# AT91SAM9X35 register map
Vendor: Atmel; Series: SAM9X; File version: 20130207
Registers are 32-bit, read-write, reset 0x0 unless marked. A register's access mark holds for its fields unless they carry their own. Offsets are from the block's base; [hi:lo] are bit positions; {n}, {i} and the like mark numbered series; 'fields as' and 'values as' point back to an identical list.

## PWM — Pulse Width Modulation Controller
Base 0xF8034000; register names take the prefix PWM_
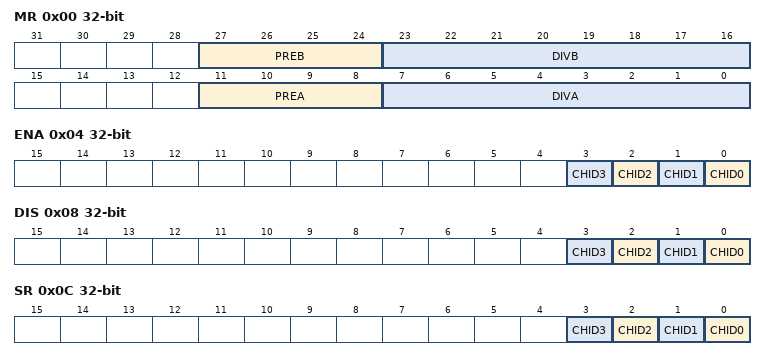
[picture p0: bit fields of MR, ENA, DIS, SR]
0x00 MR — PWM Mode Register
  [27:24] PREB
    0=MCK (Master Clock); 1=MCKDIV2 (Master Clock divided by 2); 2=MCKDIV4 (Master Clock divided by 4); 3=MCKDIV8 (Master Clock divided by 8); 4=MCKDIV16 (Master Clock divided by 16); 5=MCKDIV32 (Master Clock divided by 32); 6=MCKDIV64 (Master Clock divided by 64); 7=MCKDIV128 (Master Clock divided by 128); 8=MCKDIV256 (Master Clock divided by 256); 9=MCKDIV512 (Master Clock divided by 512); 10=MCKDIV1024 (Master Clock divided by 1024)
  [23:16] DIVB — CLKA, CLKB Divide Factor
    0=CLK_OFF (CLKA, CLKB clock is turned off); 1=CLK_DIV1 (CLKA, CLKB clock is clock selected by PREA, PREB)
  [11:8] PREA
    values as PREB
  [7:0] DIVA — CLKA, CLKB Divide Factor
    values as DIVB
0x04 ENA wo reset not defined — PWM Enable Register
  [n] CHID{n} (n=0..3) — Channel ID
0x08 DIS wo reset not defined — PWM Disable Register
  [n] CHID{n} (n=0..3) — Channel ID
0x0C SR ro — PWM Status Register
  [n] CHID{n} (n=0..3) — Channel ID
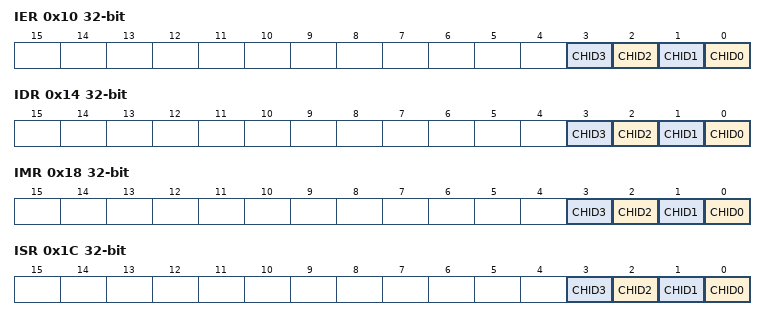
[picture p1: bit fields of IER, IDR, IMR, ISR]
0x10 IER wo reset not defined — PWM Interrupt Enable Register
  [n] CHID{n} (n=0..3) — Channel ID.
0x14 IDR wo reset not defined — PWM Interrupt Disable Register
  [n] CHID{n} (n=0..3) — Channel ID.
0x18 IMR ro — PWM Interrupt Mask Register
  [n] CHID{n} (n=0..3) — Channel ID.
0x1C ISR ro — PWM Interrupt Status Register
  [n] CHID{n} (n=0..3) — Channel ID
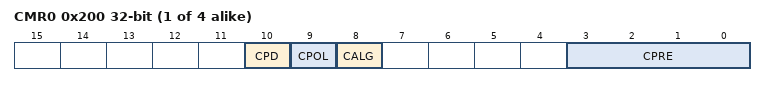
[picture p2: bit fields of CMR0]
{0x200+0x20*i} CMR{i} (i=0..3) — PWM Channel Mode Register (ch_num = {i})
  [10] CPD — Channel Update Period
  [9] CPOL — Channel Polarity
  [8] CALG — Channel Alignment
  [3:0] CPRE — Channel Pre-scaler
    0=MCK (Master Clock); 1=MCKDIV2 (Master Clock divided by 2); 2=MCKDIV4 (Master Clock divided by 4); 3=MCKDIV8 (Master Clock divided by 8); 4=MCKDIV16 (Master Clock divided by 16); 5=MCKDIV32 (Master Clock divided by 32); 6=MCKDIV64 (Master Clock divided by 64); 7=MCKDIV128 (Master Clock divided by 128); 8=MCKDIV256 (Master Clock divided by 256); 9=MCKDIV512 (Master Clock divided by 512); 10=MCKDIV1024 (Master Clock divided by 1024); 11=CLKA (Clock A); 12=CLKB (Clock B)
{0x204+0x20*i} CDTY{i} (i=0..3) — PWM Channel Duty Cycle Register (ch_num = {i})
  [31:0] CDTY — Channel Duty Cycle
{0x208+0x20*i} CPRD{i} (i=0..3) — PWM Channel Period Register (ch_num = {i})
  [31:0] CPRD — Channel Period
{0x20C+0x20*i} CCNT{i} ro (i=0..3) — PWM Channel Counter Register (ch_num = {i})
  [31:0] CNT — Channel Counter Register
{0x210+0x20*i} CUPD{i} wo reset not defined (i=0..3) — PWM Channel Update Register (ch_num = {i})
  [31:0] CUPD

## UART0 — Universal Asynchronous Receiver Transmitter 0
Base 0xF8040000; register names take the prefix UART0_
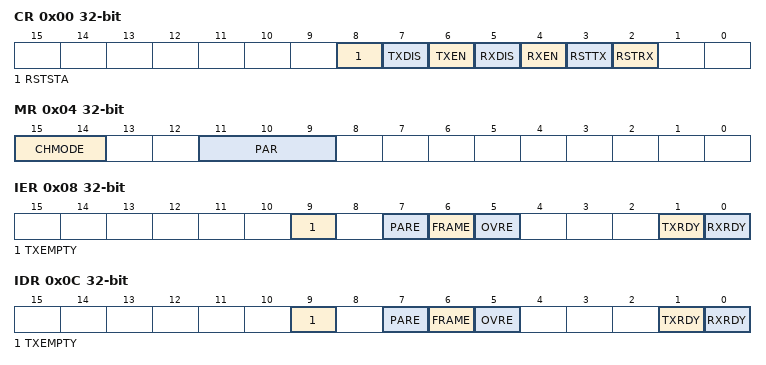
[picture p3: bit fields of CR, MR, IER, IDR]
0x00 CR wo reset not defined — Control Register
  [8] RSTSTA — Reset Status Bits
  [7] TXDIS — Transmitter Disable
  [6] TXEN — Transmitter Enable
  [5] RXDIS — Receiver Disable
  [4] RXEN — Receiver Enable
  [3] RSTTX — Reset Transmitter
  [2] RSTRX — Reset Receiver
0x04 MR — Mode Register
  [15:14] CHMODE — Channel Mode
    0=NORMAL (Normal Mode); 1=AUTOMATIC (Automatic Echo); 2=LOCAL_LOOPBACK; 3=REMOTE_LOOPBACK
  [11:9] PAR — Parity Type
    0=EVEN (Even Parity); 1=ODD (Odd Parity); 2=SPACE (Space: parity forced to 0); 3=MARK (Mark: parity forced to 1); 4=NO (No Parity)
0x08 IER wo reset not defined — Interrupt Enable Register
  [9] TXEMPTY — Enable TXEMPTY Interrupt
  [7] PARE — Enable Parity Error Interrupt
  [6] FRAME — Enable Framing Error Interrupt
  [5] OVRE — Enable Overrun Error Interrupt
  [1] TXRDY — Enable TXRDY Interrupt
  [0] RXRDY — Enable RXRDY Interrupt
0x0C IDR wo reset not defined — Interrupt Disable Register
  [9] TXEMPTY — Disable TXEMPTY Interrupt
  [7] PARE — Disable Parity Error Interrupt
  [6] FRAME — Disable Framing Error Interrupt
  [5] OVRE — Disable Overrun Error Interrupt
  [1] TXRDY — Disable TXRDY Interrupt
  [0] RXRDY — Disable RXRDY Interrupt
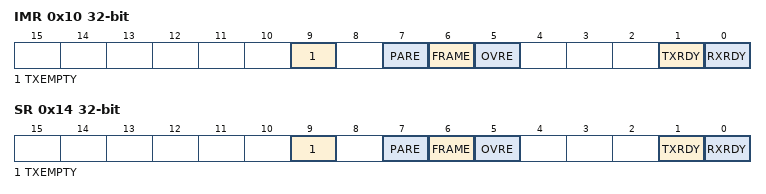
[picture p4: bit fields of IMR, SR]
0x10 IMR ro — Interrupt Mask Register
  [9] TXEMPTY — Mask TXEMPTY Interrupt
  [7] PARE — Mask Parity Error Interrupt
  [6] FRAME — Mask Framing Error Interrupt
  [5] OVRE — Mask Overrun Error Interrupt
  [1] TXRDY — Disable TXRDY Interrupt
  [0] RXRDY — Mask RXRDY Interrupt
0x14 SR ro reset not defined — Status Register
  [9] TXEMPTY — Transmitter Empty
  [7] PARE — Parity Error
  [6] FRAME — Framing Error
  [5] OVRE — Overrun Error
  [1] TXRDY — Transmitter Ready
  [0] RXRDY — Receiver Ready
0x18 RHR ro — Receive Holding Register
  [7:0] RXCHR — Received Character
0x1C THR wo reset not defined — Transmit Holding Register
  [7:0] TXCHR — Character to be Transmitted
0x20 BRGR — Baud Rate Generator Register
  [15:0] CD — Clock Divisor

## UART1 — Universal Asynchronous Receiver Transmitter 1
Base 0xF8044000; register names take the prefix UART1_
Registers as UART0.
